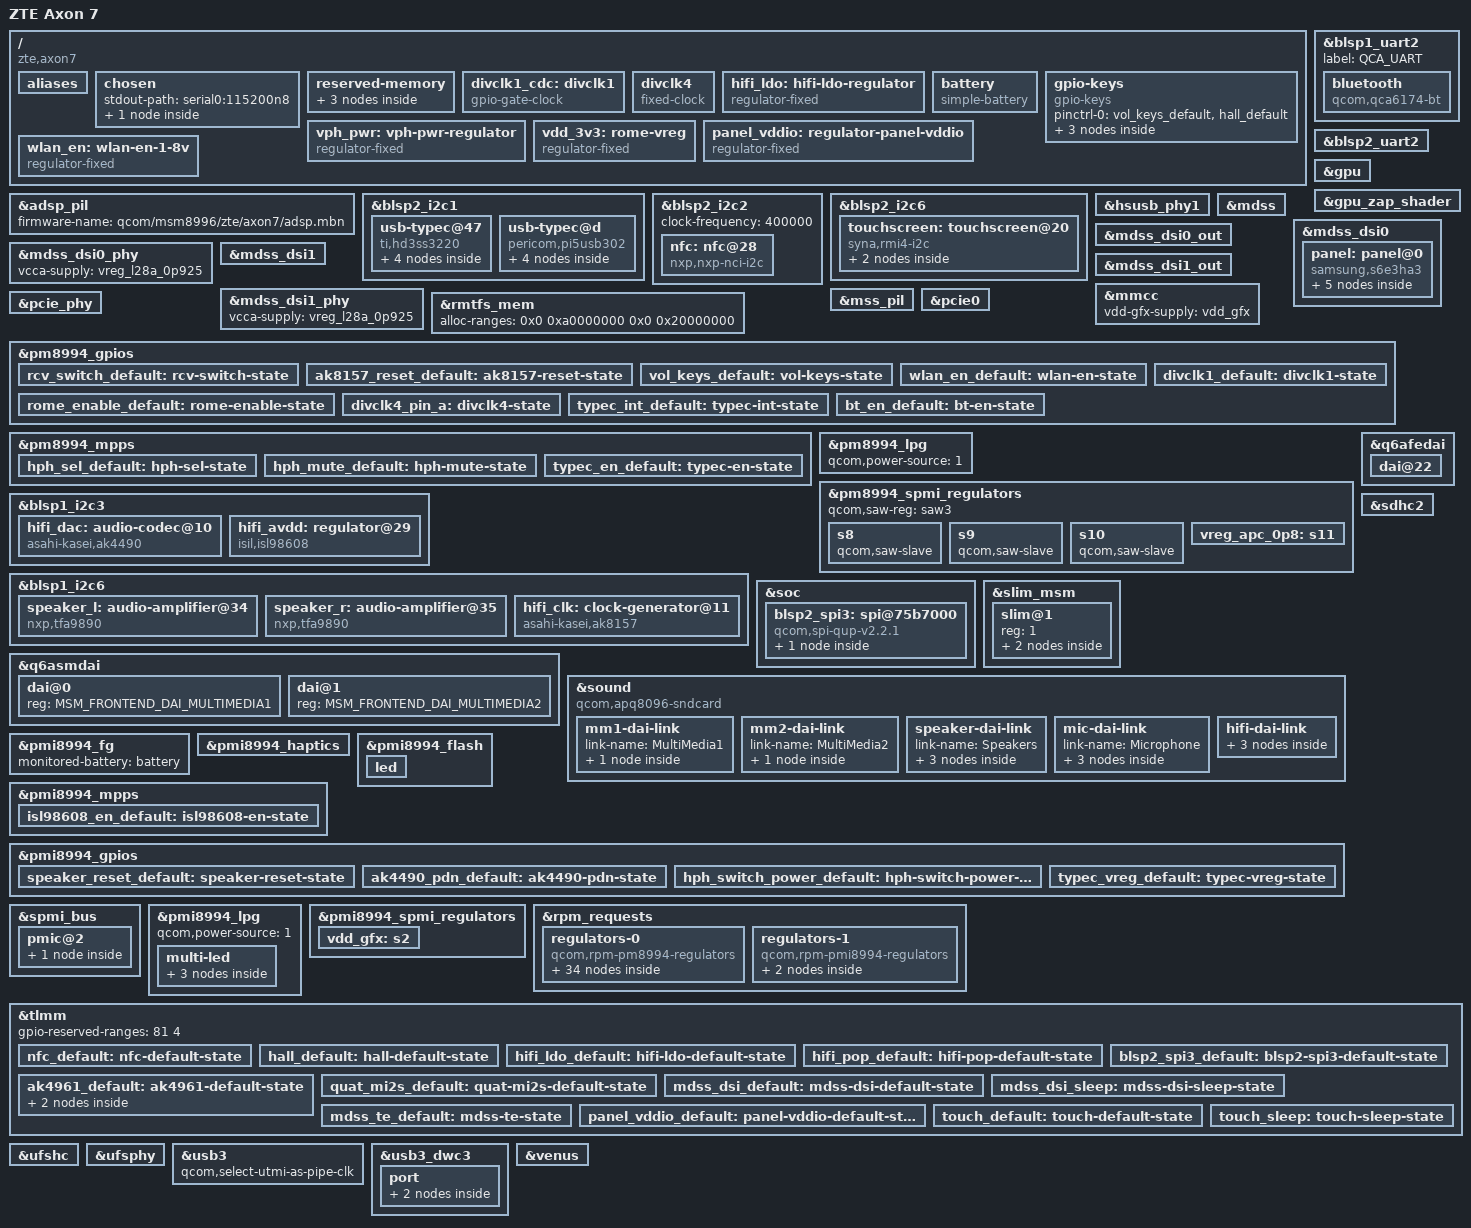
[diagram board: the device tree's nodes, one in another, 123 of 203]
// SPDX-License-Identifier: BSD-3-Clause
/*
 * ZTE Axon 7 (A2017/A2017G/A2017U, "ailsa_ii")
 *
 * Written against mainline msm8996.dtsi. Hardware description derived from
 * the device's downstream (3.18) device tree:
 *   model "Qualcomm Technologies, Inc. MSM 8996 v3 + PMI8996 MTP"
 * Board layout is very close to the Qualcomm MTP / Xiaomi msm8996 boards.
 */

/dts-v1/;

#include <dt-bindings/gpio/gpio.h>
#include <dt-bindings/input/input.h>
#include <dt-bindings/leds/common.h>
#include <dt-bindings/pinctrl/qcom,pmic-gpio.h>
#include <dt-bindings/sound/qcom,q6asm.h>
#include <dt-bindings/sound/qcom,q6dsp-lpass-ports.h>
#include "msm8996.dtsi"
#include "pm8994.dtsi"
#include "pmi8994.dtsi"
#include "pmi8996.dtsi"	/* sets qcom,pmic-id = <0x20009 0x10013 0 0>, as downstream */

/ {
	model = "ZTE Axon 7";
	compatible = "zte,axon7", "qcom,msm8996";
	chassis-type = "handset";

	/* Must match what the ZTE LK expects (taken from the downstream DT) */
	qcom,msm-id = <246 0x30001>;	/* MSM8996 v3.1 */
	qcom,board-id = <100 0>;

	aliases {
		serial0 = &blsp2_uart2;
		serial1 = &blsp1_uart2;
	};

	chosen {
		#address-cells = <2>;
		#size-cells = <2>;
		ranges;

		stdout-path = "serial0:115200n8";

		/*
		 * Bootloader continuous splash. Panel is a dual-DSI command-mode
		 * Samsung S6E3HA3 (1440x2560), bpp 24 in the downstream panel node.
		 * Format/stride are assumed (r8g8b8, 1440 * 3) as on other msm8996
		 * LK splash setups - to be confirmed on device.
		 */
		framebuffer0: framebuffer@83401000 {
			compatible = "simple-framebuffer";
			reg = <0x0 0x83401000 0x0 (1440 * 2560 * 3)>;
			width = <1440>;
			height = <2560>;
			stride = <(1440 * 3)>;
			format = "r8g8b8";

			/* MDP, both DSI links and MDP SMMU clocks */
			clocks = <&mmcc MDSS_MDP_CLK>,
				 <&mmcc MMSS_MMAGIC_AHB_CLK>,
				 <&mmcc MDSS_AHB_CLK>,
				 <&mmcc MDSS_AXI_CLK>,
				 <&mmcc MMSS_MISC_AHB_CLK>,
				 <&mmcc MDSS_BYTE0_CLK>,
				 <&mmcc MDSS_PCLK0_CLK>,
				 <&mmcc MDSS_ESC0_CLK>,
				 <&mmcc MDSS_BYTE1_CLK>,
				 <&mmcc MDSS_PCLK1_CLK>,
				 <&mmcc MDSS_ESC1_CLK>,
				 <&mmcc SMMU_MDP_AHB_CLK>,
				 <&mmcc SMMU_MDP_AXI_CLK>;

			power-domains = <&mmcc MDSS_GDSC>;
		};
	};

	reserved-memory {
		/* dfps_data_mem@83400000 (0x1000) + cont_splash_mem@83401000 (0x23ff000) */
		cont_splash_mem: memory@83400000 {
			reg = <0x0 0x83400000 0x0 0x2400000>;
			no-map;
		};

		/* Same location/layout as downstream pstore_mem, readable from TWRP */
		ramoops@bfc00000 {
			compatible = "ramoops";
			reg = <0x0 0xbfc00000 0x0 0x400000>;
			no-map;

			record-size = <0x8000>;
			console-size = <0x100000>;
			ftrace-size = <0x100000>;
			pmsg-size = <0x100000>;
		};

		/*
		 * ZTE "vlog": 1 MiB the bootloader hands to another writer
		 * (address and size in vendor IMEM); ZTE's kernel keeps it out
		 * of Linux, so do we.
		 */
		vlog@9ff00000 {
			reg = <0x0 0x9ff00000 0x0 0x100000>;
			no-map;
		};
	};

	divclk1_cdc: divclk1 {
		compatible = "gpio-gate-clock";
		clocks = <&rpmcc RPM_SMD_DIV_CLK1>;
		#clock-cells = <0>;
		enable-gpios = <&pm8994_gpios 15 GPIO_ACTIVE_HIGH>;

		pinctrl-names = "default";
		pinctrl-0 = <&divclk1_default>;
	};

	divclk4: divclk4 {
		compatible = "fixed-clock";
		#clock-cells = <0>;
		clock-frequency = <32768>;
		clock-output-names = "divclk4";

		pinctrl-names = "default";
		pinctrl-0 = <&divclk4_pin_a>;
	};

	hifi_ldo: hifi-ldo-regulator {
		compatible = "regulator-fixed";
		regulator-name = "hifi_ldo";
		gpio = <&tlmm 93 GPIO_ACTIVE_HIGH>;
		enable-active-high;
		pinctrl-names = "default";
		pinctrl-0 = <&hifi_ldo_default>;
	};

	/* ZTE P996A01, 3250 mAh, float voltage 4.4 V (zte_p996a01_3250mah.dtsi) */
	battery: battery {
		compatible = "simple-battery";
		charge-full-design-microamp-hours = <3250000>;
		voltage-min-design-microvolt = <3400000>;
		voltage-max-design-microvolt = <4400000>;
	};

	gpio-keys {
		compatible = "gpio-keys";

		pinctrl-names = "default";
		pinctrl-0 = <&vol_keys_default>, <&hall_default>;

		key-vol-up {
			label = "Volume Up";
			gpios = <&pm8994_gpios 2 GPIO_ACTIVE_LOW>;
			linux,code = <KEY_VOLUMEUP>;
			wakeup-source;
			debounce-interval = <15>;
		};

		key-vol-down {
			label = "Volume Down";
			gpios = <&pm8994_gpios 3 GPIO_ACTIVE_LOW>;
			linux,code = <KEY_VOLUMEDOWN>;
			wakeup-source;
			debounce-interval = <15>;
		};

		/*
		 * Hall sensor (downstream "zte-hall"/"ah,hall_ic", TLMM 124):
		 * high = cover open, low = cover closed (ZTE's ah1898.c). It is
		 * powered from PM8994 LVS2, which is kept on for it.
		 */
		event-hall-sensor {
			label = "Hall Effect Sensor";
			gpios = <&tlmm 124 GPIO_ACTIVE_LOW>;
			linux,input-type = <EV_SW>;
			linux,code = <SW_LID>;
			linux,can-disable;
			wakeup-source;
			debounce-interval = <150>;
		};
	};

	vph_pwr: vph-pwr-regulator {
		compatible = "regulator-fixed";
		regulator-name = "vph_pwr";
		regulator-min-microvolt = <3700000>;
		regulator-max-microvolt = <3700000>;
		regulator-always-on;
		regulator-boot-on;
	};

	/* downstream "rome_vreg", PM8994 GPIO 9 */
	vdd_3v3: rome-vreg {
		compatible = "regulator-fixed";
		regulator-name = "vdd_3v3";
		regulator-min-microvolt = <3300000>;
		regulator-max-microvolt = <3300000>;
		startup-delay-us = <4000>;
		vin-supply = <&vph_pwr_bbyp>;

		gpio = <&pm8994_gpios 9 GPIO_ACTIVE_HIGH>;
		enable-active-high;
		pinctrl-names = "default";
		pinctrl-0 = <&rome_enable_default>;

		/* Required by QCA6174a - vddpe-3v3 */
		regulator-always-on;
	};

	/* WL_EN pin (PM8994 GPIO 8) defined as a fixed regulator */
	/* panel VDD3 (1.8 V), downstream zte,lcd-3v-vsp-enable-gpio */
	panel_vddio: regulator-panel-vddio {
		compatible = "regulator-fixed";
		regulator-name = "panel_vddio";
		regulator-min-microvolt = <1800000>;
		regulator-max-microvolt = <1800000>;

		gpio = <&tlmm 40 GPIO_ACTIVE_HIGH>;
		enable-active-high;
		regulator-boot-on;

		pinctrl-names = "default";
		pinctrl-0 = <&panel_vddio_default>;
	};

	wlan_en: wlan-en-1-8v {
		compatible = "regulator-fixed";
		regulator-name = "wlan-en-regulator";
		regulator-min-microvolt = <1800000>;
		regulator-max-microvolt = <1800000>;

		gpio = <&pm8994_gpios 8 GPIO_ACTIVE_HIGH>;
		/* WLAN card specific delay */
		startup-delay-us = <70000>;
		enable-active-high;
		pinctrl-names = "default";
		pinctrl-0 = <&wlan_en_default>;
	};
};

&adsp_pil {
	status = "okay";
	firmware-name = "qcom/msm8996/zte/axon7/adsp.mbn";
};

&blsp1_uart2 {
	status = "okay";
	label = "QCA_UART";

	bluetooth: bluetooth {
		compatible = "qcom,qca6174-bt";

		/* bt_disable_n */
		enable-gpios = <&pm8994_gpios 19 GPIO_ACTIVE_HIGH>;
		clocks = <&divclk4>;

		pinctrl-names = "default";
		pinctrl-0 = <&bt_en_default>;
	};
};

/* Debug UART (downstream ttyHSL0) */
&blsp2_uart2 {
	status = "okay";
	label = "LS-UART1";
	pinctrl-names = "default", "sleep";
	pinctrl-0 = <&blsp2_uart2_2pins_default>;
	pinctrl-1 = <&blsp2_uart2_2pins_sleep>;
};

/*
 * i2c@7577000: isl98608@29 (hi-fi supply), ak4490@10 (AK4490 DAC)
 * i2c@757a000: ak8157@11
 * No mainline drivers yet, buses left disabled.
 */

/*
 * i2c@75b5000: TI HD3SS3220 USB-C controller @47 and SMB1351 parallel
 * charger @1d (no driver). Downstream zte-usb-type-c.dtsi: INT = PM8994
 * GPIO 14, EN_CC/mux = PM8994 MPP 5, SS re-driver = MPP 7, chip supplies
 * from PMI8994 GPIO 8 (VCONN 5 V) and GPIO 9 (3.3 V), all driven high.
 * Some units carry a Pericom PI5USB302 @0d instead: then this probe fails
 * and dwc3 stays in its default peripheral role (USB networking keeps
 * working). VBUS for host mode comes from the PMI8994 SMBCHG OTG boost.
 */
&blsp2_i2c1 {
	status = "okay";

	usb-typec@47 {
		compatible = "ti,hd3ss3220";
		reg = <0x47>;

		/* same trigger as the PI5USB302 node: both map PM8994 GPIO 14 */
		interrupts-extended = <&pm8994_gpios 14 IRQ_TYPE_LEVEL_LOW>;

		pinctrl-names = "default";
		pinctrl-0 = <&typec_int_default>, <&typec_en_default>, <&typec_vreg_default>;

		connector {
			compatible = "usb-c-connector";
			label = "USB-C";
			data-role = "dual";
			power-role = "dual";
			try-power-role = "sink";
			typec-power-opmode = "default";

			vbus-supply = <&smbchg_otg_vbus>;

			ports {
				#address-cells = <1>;
				#size-cells = <0>;

				port@0 {
					reg = <0>;

					typec_hs_out: endpoint {
						remote-endpoint = <&usb3_dwc3_role_in>;
					};
				};
			};
		};
	};

	/*
	 * Other units carry a Pericom PI5USB302 instead (downstream lists
	 * both, same INT and enables); this phone answers at 0x0d only.
	 */
	usb-typec@d {
		compatible = "pericom,pi5usb302";
		reg = <0x0d>;

		interrupts-extended = <&pm8994_gpios 14 IRQ_TYPE_LEVEL_LOW>;

		pinctrl-names = "default";
		pinctrl-0 = <&typec_int_default>, <&typec_en_default>, <&typec_vreg_default>;

		connector {
			compatible = "usb-c-connector";
			label = "USB-C";
			data-role = "dual";
			power-role = "dual";
			try-power-role = "sink";
			typec-power-opmode = "default";

			vbus-supply = <&smbchg_otg_vbus>;

			ports {
				#address-cells = <1>;
				#size-cells = <0>;

				port@0 {
					reg = <0>;

					pi5usb_hs_out: endpoint {
						remote-endpoint = <&usb3_dwc3_role_pi>;
					};
				};
			};
		};
	};
};

&blsp2_i2c2 {
	status = "okay";
	clock-frequency = <400000>;

	/* downstream "qcom,nq-nci" (NXP PN5xx) */
	nfc: nfc@28 {
		compatible = "nxp,nxp-nci-i2c";
		reg = <0x28>;

		interrupt-parent = <&tlmm>;
		interrupts = <9 IRQ_TYPE_LEVEL_HIGH>;

		enable-gpios = <&tlmm 12 GPIO_ACTIVE_HIGH>;
		firmware-gpios = <&tlmm 96 GPIO_ACTIVE_HIGH>;

		pinctrl-names = "default";
		pinctrl-0 = <&nfc_default>;
	};
};

&blsp2_i2c6 {
	status = "okay";

	/* Synaptics DSX (S3320-class) */
	touchscreen: touchscreen@20 {
		compatible = "syna,rmi4-i2c";
		reg = <0x20>;
		#address-cells = <1>;
		#size-cells = <0>;

		interrupts-extended = <&tlmm 125 IRQ_TYPE_LEVEL_LOW>;
		reset-gpios = <&tlmm 89 GPIO_ACTIVE_LOW>;

		/* downstream: vdd_ana = L14 (1.8 V), vcc_i2c = L22 (3.3 V) */
		vdd-supply = <&vreg_l22a_3p3>;
		vio-supply = <&vreg_l14a_1p8>;

		pinctrl-names = "default", "sleep";
		pinctrl-0 = <&touch_default>;
		pinctrl-1 = <&touch_sleep>;

		syna,reset-delay-ms = <100>;
		syna,startup-delay-ms = <100>;

		rmi4-f01@1 {
			reg = <0x1>;
			syna,nosleep-mode = <1>;
		};

		rmi4-f12@12 {
			reg = <0x12>;
			syna,sensor-type = <1>;
			touchscreen-x-mm = <68>;
			touchscreen-y-mm = <121>;
		};
	};

	/* ndt,stress-i2c pressure sensor @50: no mainline driver */
};

&gpu {
	status = "okay";
};

&gpu_zap_shader {
	firmware-name = "qcom/msm8996/zte/axon7/a530_zap.mbn";
};

&hsusb_phy1 {
	status = "okay";

	vdd-supply = <&vreg_l28a_0p925>;
	vdda-pll-supply = <&vreg_l12a_1p8>;
	vdda-phy-dpdm-supply = <&vreg_l24a_3p075>;
};

/*
 * Display: Samsung S6E3HA3 1440x2560 AMOLED, command mode, over both DSI
 * links (bonded DSI, DSI0 master, each link one 720x2560 half). Bonded DSI
 * needs the DPU driver (msm.prefer_mdp5=0); MDP5 drives single DSI only.
 * simplefb above keeps LK's splash until the DRM driver takes over.
 */
&mdss {
	status = "okay";
};

&mdss_dsi0 {
	status = "okay";

	vdda-supply = <&vreg_l2a_1p25>;
	vcca-supply = <&vreg_l28a_0p925>;
	vddio-supply = <&vreg_l14a_1p8>;

	qcom,dual-dsi-mode;
	qcom,master-dsi;
	qcom,sync-dual-dsi;

	pinctrl-names = "default", "sleep";
	pinctrl-0 = <&mdss_dsi_default &mdss_te_default>;
	pinctrl-1 = <&mdss_dsi_sleep &mdss_te_default>;

	panel: panel@0 {
		compatible = "samsung,s6e3ha3";
		reg = <0>;

		vddio-supply = <&panel_vddio>;
		vdda-supply = <&vreg_l19a_3p0>;
		reset-gpios = <&tlmm 8 GPIO_ACTIVE_LOW>;

		ports {
			#address-cells = <1>;
			#size-cells = <0>;

			port@0 {
				reg = <0>;

				panel_in0: endpoint {
					remote-endpoint = <&mdss_dsi0_out>;
				};
			};

			port@1 {
				reg = <1>;

				panel_in1: endpoint {
					remote-endpoint = <&mdss_dsi1_out>;
				};
			};
		};
	};
};

&mdss_dsi0_out {
	remote-endpoint = <&panel_in0>;
	data-lanes = <0 1 2 3>;
};

&mdss_dsi0_phy {
	status = "okay";

	vcca-supply = <&vreg_l28a_0p925>;
};

&mdss_dsi1 {
	status = "okay";

	vdda-supply = <&vreg_l2a_1p25>;
	vcca-supply = <&vreg_l28a_0p925>;
	vddio-supply = <&vreg_l14a_1p8>;

	qcom,dual-dsi-mode;
	qcom,sync-dual-dsi;

	/* bonded: DSI1 runs from DSI0's PLL */
	assigned-clock-parents = <&mdss_dsi0_phy DSI_BYTE_PLL_CLK>,
				 <&mdss_dsi0_phy DSI_PIXEL_PLL_CLK>;
};

&mdss_dsi1_out {
	remote-endpoint = <&panel_in1>;
	data-lanes = <0 1 2 3>;
};

&mdss_dsi1_phy {
	status = "okay";

	vcca-supply = <&vreg_l28a_0p925>;
};

&mmcc {
	vdd-gfx-supply = <&vdd_gfx>;
};

/*
 * The bootloader loads the kernel and initramfs at 0xa0000000, inside the
 * 32 MiB the SoC dtsi allows for rmtfs: no room is left and the modem cannot
 * start. Allow the whole 512 MiB above it.
 */
&rmtfs_mem {
	alloc-ranges = <0x0 0xa0000000 0x0 0x20000000>;
};

&mss_pil {
	status = "okay";

	pll-supply = <&vreg_l12a_1p8>;

	firmware-name = "qcom/msm8996/zte/axon7/mba.mbn",
			"qcom/msm8996/zte/axon7/modem.mbn";
};

&pcie0 {
	status = "okay";

	/* Supplied by vdd_3v3, but choose wlan_en to drive enable pin high */
	vddpe-3v3-supply = <&wlan_en>;
	vdda-supply = <&vreg_l28a_0p925>;

	perst-gpios = <&tlmm 35 GPIO_ACTIVE_LOW>;
	wake-gpios = <&tlmm 37 GPIO_ACTIVE_HIGH>;
};

&pcie_phy {
	status = "okay";

	vdda-phy-supply = <&vreg_l28a_0p925>;
	vdda-pll-supply = <&vreg_l12a_1p8>;
};

&pm8994_gpios {
	/* earpiece switch (ZTE qcom,rcv-sw-gpio) */
	rcv_switch_default: rcv-switch-state {
		pins = "gpio13";
		function = PMIC_GPIO_FUNC_NORMAL;
		output-low;
		bias-disable;
		power-source = <PM8994_GPIO_S4>;
	};

	/* Hi-Fi: AK8157 clock generator reset (GPIO 1, and GPIO 12 as in ZTE's tree) */
	ak8157_reset_default: ak8157-reset-state {
		pins = "gpio1", "gpio12";
		function = PMIC_GPIO_FUNC_NORMAL;
		output-low;
		bias-disable;
		power-source = <PM8994_GPIO_S4>;
	};

	vol_keys_default: vol-keys-state {
		pins = "gpio2", "gpio3";
		function = PMIC_GPIO_FUNC_NORMAL;
		input-enable;
		bias-pull-up;
		qcom,drive-strength = <PMIC_GPIO_STRENGTH_NO>;
		power-source = <PM8994_GPIO_S4>;
	};

	wlan_en_default: wlan-en-state {
		pins = "gpio8";
		function = PMIC_GPIO_FUNC_NORMAL;
		output-low;
		qcom,drive-strength = <PMIC_GPIO_STRENGTH_LOW>;
		power-source = <PM8994_GPIO_S4>;
		bias-disable;
	};

	rome_enable_default: rome-enable-state {
		pins = "gpio9";
		function = PMIC_GPIO_FUNC_NORMAL;
		output-high;
		qcom,drive-strength = <PMIC_GPIO_STRENGTH_LOW>;
		power-source = <PM8994_GPIO_VPH>;
	};

	divclk1_default: divclk1-state {
		pins = "gpio15";
		function = PMIC_GPIO_FUNC_FUNC1;
		bias-disable;
		power-source = <PM8994_GPIO_S4>;
		qcom,drive-strength = <PMIC_GPIO_STRENGTH_LOW>;
	};

	divclk4_pin_a: divclk4-state {
		pins = "gpio18";
		function = PMIC_GPIO_FUNC_FUNC2;
		bias-disable;
		power-source = <PM8994_GPIO_S4>;
	};

	typec_int_default: typec-int-state {
		pins = "gpio14";
		function = PMIC_GPIO_FUNC_NORMAL;
		input-enable;
		bias-disable;
		power-source = <PM8994_GPIO_S4>;
	};

	bt_en_default: bt-en-state {
		pins = "gpio19";
		function = PMIC_GPIO_FUNC_NORMAL;
		output-low;
		power-source = <PM8994_GPIO_S4>;
		qcom,drive-strength = <PMIC_GPIO_STRENGTH_LOW>;
		bias-pull-down;
	};
};

&pm8994_mpps {
	/* Hi-Fi: ISL54405 headphone switch select, MPP 2 (0 = AK4490, 1 = AK4961) */
	hph_sel_default: hph-sel-state {
		pins = "mpp2";
		function = "digital";
		output-low;
		power-source = <2>;
	};

	/* Hi-Fi: ISL54405 mute, MPP 4 (1 = muted) */
	hph_mute_default: hph-mute-state {
		pins = "mpp4";
		function = "digital";
		output-high;
		power-source = <2>;
	};

	typec_en_default: typec-en-state {
		/* MPP 5: EN_CC / USB 3.0 mux, MPP 7: SS re-driver; enabled high */
		pins = "mpp5", "mpp7";
		function = "digital";
		output-high;
		power-source = <2>;
	};
};

&pm8994_lpg {
	status = "okay";

	qcom,power-source = <1>;
};

&pm8994_spmi_regulators {
	qcom,saw-reg = <&saw3>;

	s8 {
		qcom,saw-slave;
	};

	s9 {
		qcom,saw-slave;
	};

	s10 {
		qcom,saw-slave;
	};

	vreg_apc_0p8: s11 {
		qcom,saw-leader;
		regulator-name = "vreg_apc_0p8";
		regulator-min-microvolt = <470000>;
		regulator-max-microvolt = <1140000>;
		regulator-max-step-microvolt = <150000>;
		regulator-always-on;
	};
};

/* Notification LED, downstream qpnp RGB (ids 3/4/5 = R/G/B) */
/*
 * Hi-Fi headphone path (ZTE's msm-3.18 tree): AK4490 DAC and ISL98608
 * supply on BLSP1 QUP3, AK8157 clock generator (the I2S clock provider)
 * on BLSP1 QUP6, Quaternary MI2S from the ADSP, and an ISL54405 switch
 * that connects the jack to the AK4490 (or to the AK4961, which has no
 * driver yet, so the switch stays on the AK4490).
 */
&blsp1_i2c3 {
	status = "okay";

	hifi_dac: audio-codec@10 {
		compatible = "asahi-kasei,ak4490";
		reg = <0x10>;
		#sound-dai-cells = <0>;

		dvdd-supply = <&hifi_ldo>;
		avdd-supply = <&hifi_avdd>;
		pdn-gpios = <&pmi8994_gpios 1 GPIO_ACTIVE_LOW>;
		/* ISL54405 mute, high = muted */
		mute-gpios = <&pm8994_mpps 4 GPIO_ACTIVE_HIGH>;

		pinctrl-names = "default";
		pinctrl-0 = <&ak4490_pdn_default &hph_mute_default &hph_sel_default
			     &hph_switch_power_default &hifi_pop_default>;
	};

	hifi_avdd: regulator@29 {
		compatible = "isil,isl98608";
		reg = <0x29>;
		regulator-name = "hifi_avdd";
		enable-gpios = <&pmi8994_mpps 4 GPIO_ACTIVE_HIGH>;

		pinctrl-names = "default";
		pinctrl-0 = <&isl98608_en_default>;
	};
};

&blsp1_i2c6 {
	status = "okay";

	/*
	 * TFA9890 speaker amplifiers, fed by the AK4961's PORT2 (SDTO2) I2S;
	 * resets on PMI8994 GPIO 2/3 (low = running). 0x34 drives the bottom
	 * speaker (next to the microphone), 0x35 the top one, which the
	 * receiver switch turns into the earpiece (measured with the
	 * microphone, 2026-11-09).
	 */
	speaker_l: audio-amplifier@34 {
		compatible = "nxp,tfa9890";
		reg = <0x34>;
		#sound-dai-cells = <0>;
		sound-name-prefix = "Speaker Bottom";
		vddd-supply = <&vreg_s4a_1p8>;

		pinctrl-names = "default";
		pinctrl-0 = <&speaker_reset_default>;
	};

	speaker_r: audio-amplifier@35 {
		compatible = "nxp,tfa9890";
		reg = <0x35>;
		#sound-dai-cells = <0>;
		sound-name-prefix = "Speaker Top";
		vddd-supply = <&vreg_s4a_1p8>;
		/* ZTE's "Receiver Switch" (PM8994 GPIO 13): top speaker as earpiece */
		rcv-gpios = <&pm8994_gpios 13 GPIO_ACTIVE_HIGH>;

		pinctrl-names = "default";
		pinctrl-0 = <&rcv_switch_default>;
	};

	hifi_clk: clock-generator@11 {
		compatible = "asahi-kasei,ak8157";
		reg = <0x11>;
		#sound-dai-cells = <0>;
		reset-gpios = <&pm8994_gpios 1 GPIO_ACTIVE_LOW>,
			      <&pm8994_gpios 12 GPIO_ACTIVE_LOW>;

		pinctrl-names = "default";
		pinctrl-0 = <&ak8157_reset_default>;
	};
};

/*
 * AK4961 main codec (speaker, earpiece, microphones, headset). ZTE runs it
 * in "SLIMbus + SPI" mode: registers over SPI on BLSP2 QUP3 (CIF1 low),
 * audio data and the port arrays over SLIMbus.
 */
&soc {
	blsp2_spi3: spi@75b7000 {
		compatible = "qcom,spi-qup-v2.2.1";
		reg = <0x075b7000 0x600>;
		interrupts = <GIC_SPI 103 IRQ_TYPE_LEVEL_HIGH>;
		clocks = <&gcc GCC_BLSP2_QUP3_SPI_APPS_CLK>,
			 <&gcc GCC_BLSP2_AHB_CLK>;
		clock-names = "core", "iface";
		dmas = <&blsp2_dma 16>, <&blsp2_dma 17>;
		dma-names = "tx", "rx";
		pinctrl-names = "default";
		pinctrl-0 = <&blsp2_spi3_default>;
		#address-cells = <1>;
		#size-cells = <0>;

		ak4961_spi: codec@0 {
			compatible = "asahi-kasei,ak4961-spi";
			reg = <0>;
			spi-max-frequency = <9600000>;
		};
	};
};

&slim_msm {
	status = "okay";

	slim@1 {
		reg = <1>;
		#address-cells = <2>;
		#size-cells = <0>;

		ak4961_ifd: ifd@0,0 {
			compatible = "slim1dd,4961";
			reg = <0 0>;
		};

		ak4961: codec@2,0 {
			compatible = "slim1dd,4961";
			reg = <2 0>;
			#sound-dai-cells = <1>;

			slim-ifc-dev = <&ak4961_ifd>;
			akm,spi = <&ak4961_spi>;

			clocks = <&divclk1_cdc>;
			clock-names = "mclk";

			ldo-gpios = <&tlmm 63 GPIO_ACTIVE_HIGH>;
			cif-gpios = <&tlmm 62 GPIO_ACTIVE_HIGH>;
			reset-gpios = <&tlmm 64 GPIO_ACTIVE_LOW>;

			pinctrl-names = "default";
			pinctrl-0 = <&ak4961_default>;
		};
	};
};

&q6afedai {
	dai@22 {
		reg = <QUATERNARY_MI2S_RX>;
		/* ZTE: qcom,msm-mi2s-rx-lines = <2> (bit 1, SD1 on TLMM 61) */
		qcom,sd-lines = <1>;
	};
};

&q6asmdai {
	dai@0 {
		reg = <MSM_FRONTEND_DAI_MULTIMEDIA1>;
	};

	dai@1 {
		reg = <MSM_FRONTEND_DAI_MULTIMEDIA2>;
	};
};

&sound {
	compatible = "qcom,apq8096-sndcard";
	model = "ZTE Axon 7";

	pinctrl-names = "default";
	pinctrl-0 = <&quat_mi2s_default>;

	mm1-dai-link {
		link-name = "MultiMedia1";

		cpu {
			sound-dai = <&q6asmdai MSM_FRONTEND_DAI_MULTIMEDIA1>;
		};
	};

	mm2-dai-link {
		link-name = "MultiMedia2";

		cpu {
			sound-dai = <&q6asmdai MSM_FRONTEND_DAI_MULTIMEDIA2>;
		};
	};

	speaker-dai-link {
		link-name = "Speakers";

		cpu {
			sound-dai = <&q6afedai SLIMBUS_0_RX>;
		};

		platform {
			sound-dai = <&q6routing>;
		};

		codec {
			sound-dai = <&ak4961 0>, <&speaker_l>, <&speaker_r>;
		};
	};

	mic-dai-link {
		link-name = "Microphone";

		cpu {
			sound-dai = <&q6afedai SLIMBUS_0_TX>;
		};

		platform {
			sound-dai = <&q6routing>;
		};

		codec {
			sound-dai = <&ak4961 1>;
		};
	};

	hifi-dai-link {
		link-name = "Hi-Fi Headphones";
		/* BCLK and WS come from the AK8157 */
		qcom,mi2s-clock-consumer;

		cpu {
			sound-dai = <&q6afedai QUATERNARY_MI2S_RX>;
		};

		platform {
			sound-dai = <&q6routing>;
		};

		codec {
			sound-dai = <&hifi_dac>, <&hifi_clk>;
		};
	};
};

&pmi8994_fg {
	/* read-only: no charger driver yet, so no "power-supplies" */
	monitored-battery = <&battery>;
	status = "okay";
};

/* LRA vibrator, ZTE's msm-pmi8994.dtsi values (buffer mode, sine) */
&pmi8994_haptics {
	qcom,wave-play-rate-us = <4255>;
	qcom,brake-pattern = [03 03 00 00];
	qcom,vmax-microvolt = <2668000>;
	status = "okay";
};

/* rear dual-tone flash, torch mode */
&pmi8994_flash {
	status = "okay";

	led {
		function = LED_FUNCTION_TORCH;
		color = <LED_COLOR_ID_WHITE>;
	};
};

&pmi8994_mpps {
	/* Hi-Fi: ISL98608 supply enable (MPP 4) */
	isl98608_en_default: isl98608-en-state {
		pins = "mpp4";
		function = "digital";
		output-low;
		power-source = <2>;
	};
};

&pmi8994_gpios {
	/* TFA9890 speaker amplifier resets (GPIO 2 and 3, ZTE SPKR_SD_N), low = running */
	speaker_reset_default: speaker-reset-state {
		pins = "gpio2", "gpio3";
		function = PMIC_GPIO_FUNC_NORMAL;
		output-low;
		bias-disable;
		power-source = <PM8994_GPIO_S4>;
	};

	/* Hi-Fi: AK4490 PDN (GPIO 1), ISL54405 switch power (GPIO 10) */
	ak4490_pdn_default: ak4490-pdn-state {
		pins = "gpio1";
		function = PMIC_GPIO_FUNC_NORMAL;
		output-low;
		bias-disable;
		power-source = <PM8994_GPIO_S4>;
	};

	hph_switch_power_default: hph-switch-power-state {
		pins = "gpio10";
		function = PMIC_GPIO_FUNC_NORMAL;
		output-high;
		bias-disable;
		power-source = <PM8994_GPIO_S4>;
	};

	typec_vreg_default: typec-vreg-state {
		/* GPIO 8: VCONN 5 V regulator enable, GPIO 9: HD3SS3220 3.3 V */
		pins = "gpio8", "gpio9";
		function = PMIC_GPIO_FUNC_NORMAL;
		output-high;
		power-source = <PM8994_GPIO_VPH>;
		qcom,drive-strength = <PMIC_GPIO_STRENGTH_LOW>;
	};
};

&spmi_bus {
	pmic@2 {
		/* SMBCHG OTG (0x1100) and BAT_IF (0x1200) peripherals */
		smbchg_otg_vbus: usb-vbus-regulator@1100 {
			compatible = "qcom,pmi8994-smbchg-otg";
			reg = <0x1100>, <0x1200>;
			regulator-name = "smbchg_otg_vbus";
			regulator-min-microvolt = <5000000>;
			regulator-max-microvolt = <5000000>;
		};
	};
};

&pmi8994_lpg {
	status = "okay";

	qcom,power-source = <1>;

	multi-led {
		color = <LED_COLOR_ID_RGB>;
		function = LED_FUNCTION_STATUS;

		#address-cells = <1>;
		#size-cells = <0>;

		led@1 {
			reg = <1>;
			color = <LED_COLOR_ID_BLUE>;
		};

		led@2 {
			reg = <2>;
			color = <LED_COLOR_ID_GREEN>;
		};

		led@3 {
			reg = <3>;
			color = <LED_COLOR_ID_RED>;
		};
	};
};

&pmi8994_spmi_regulators {
	vdd_gfx: s2 {
		regulator-name = "vdd_gfx";
		regulator-min-microvolt = <400000>;
		regulator-max-microvolt = <1015000>;
		regulator-enable-ramp-delay = <500>;
	};
};

&rpm_requests {
	regulators-0 {
		compatible = "qcom,rpm-pm8994-regulators";

		vdd_s1-supply = <&vph_pwr>;
		vdd_s2-supply = <&vph_pwr>;
		vdd_s3-supply = <&vph_pwr>;
		vdd_s4-supply = <&vph_pwr>;
		vdd_s5-supply = <&vph_pwr>;
		vdd_s6-supply = <&vph_pwr>;
		vdd_s7-supply = <&vph_pwr>;
		vdd_s8-supply = <&vph_pwr>;
		vdd_s9-supply = <&vph_pwr>;
		vdd_s10-supply = <&vph_pwr>;
		vdd_s11-supply = <&vph_pwr>;
		vdd_s12-supply = <&vph_pwr>;
		vdd_l1-supply = <&vreg_s1b_1p025>;
		vdd_l2_l26_l28-supply = <&vreg_s3a_1p3>;
		vdd_l3_l11-supply = <&vreg_s3a_1p3>;
		vdd_l4_l27_l31-supply = <&vreg_s3a_1p3>;
		vdd_l5_l7-supply = <&vreg_s5a_2p15>;
		vdd_l6_l12_l32-supply = <&vreg_s5a_2p15>;
		vdd_l8_l16_l30-supply = <&vph_pwr>;
		vdd_l9_l10_l18_l22-supply = <&vph_pwr_bbyp>;
		vdd_l13_l19_l23_l24-supply = <&vph_pwr_bbyp>;
		vdd_l14_l15-supply = <&vreg_s5a_2p15>;
		vdd_l17_l29-supply = <&vph_pwr_bbyp>;
		vdd_l20_l21-supply = <&vph_pwr_bbyp>;
		vdd_l25-supply = <&vreg_s3a_1p3>;
		vdd_lvs1_2-supply = <&vreg_s4a_1p8>;

		/* Voltages below are from the downstream rpm-regulator nodes */
		vreg_s3a_1p3: s3 {
			regulator-name = "vreg_s3a_1p3";
			regulator-min-microvolt = <1300000>;
			regulator-max-microvolt = <1300000>;

			/* Required by QCA6174a - vdd-core */
			regulator-always-on;
		};

		vreg_s4a_1p8: s4 {
			regulator-name = "vreg_s4a_1p8";
			regulator-min-microvolt = <1800000>;
			regulator-max-microvolt = <1800000>;
			regulator-allow-set-load;

			/* Required by QCA6174a - vddio, also UFS vccq2 */
			regulator-always-on;
		};

		vreg_s5a_2p15: s5 {
			regulator-name = "vreg_s5a_2p15";
			regulator-min-microvolt = <2150000>;
			regulator-max-microvolt = <2150000>;
		};

		vreg_s7a_0p8: s7 {
			regulator-name = "vreg_s7a_0p8";
			regulator-min-microvolt = <800000>;
			regulator-max-microvolt = <800000>;
		};

		vreg_l1a_1p0: l1 {
			regulator-name = "vreg_l1a_1p0";
			regulator-min-microvolt = <1000000>;
			regulator-max-microvolt = <1000000>;
		};

		vreg_l2a_1p25: l2 {
			regulator-name = "vreg_l2a_1p25";
			regulator-min-microvolt = <1250000>;
			regulator-max-microvolt = <1250000>;
		};

		vreg_l3a_0p85: l3 {
			regulator-name = "vreg_l3a_0p85";
			regulator-min-microvolt = <850000>;
			regulator-max-microvolt = <850000>;
		};

		vreg_l4a_1p225: l4 {
			regulator-name = "vreg_l4a_1p225";
			regulator-min-microvolt = <1225000>;
			regulator-max-microvolt = <1225000>;
		};

		vreg_l6a_1p2: l6 {
			regulator-name = "vreg_l6a_1p2";
			regulator-min-microvolt = <1200000>;
			regulator-max-microvolt = <1200000>;
		};

		vreg_l8a_1p8: l8 {
			regulator-name = "vreg_l8a_1p8";
			regulator-min-microvolt = <1800000>;
			regulator-max-microvolt = <1800000>;
		};

		vreg_l9a_1p8: l9 {
			regulator-name = "vreg_l9a_1p8";
			regulator-min-microvolt = <1800000>;
			regulator-max-microvolt = <1800000>;
		};

		vreg_l10a_1p8: l10 {
			regulator-name = "vreg_l10a_1p8";
			regulator-min-microvolt = <1800000>;
			regulator-max-microvolt = <1800000>;
		};

		vreg_l11a_1p15: l11 {
			regulator-name = "vreg_l11a_1p15";
			regulator-min-microvolt = <1150000>;
			regulator-max-microvolt = <1150000>;
		};

		vreg_l12a_1p8: l12 {
			regulator-name = "vreg_l12a_1p8";
			regulator-min-microvolt = <1800000>;
			regulator-max-microvolt = <1800000>;
			regulator-allow-set-load;
		};

		vreg_l13a_2p95: l13 {
			regulator-name = "vreg_l13a_2p95";
			regulator-min-microvolt = <1800000>;
			regulator-max-microvolt = <2950000>;
		};

		vreg_l14a_1p8: l14 {
			regulator-name = "vreg_l14a_1p8";
			regulator-min-microvolt = <1800000>;
			regulator-max-microvolt = <1800000>;
		};

		vreg_l15a_1p8: l15 {
			regulator-name = "vreg_l15a_1p8";
			regulator-min-microvolt = <1800000>;
			regulator-max-microvolt = <1800000>;
		};

		vreg_l16a_2p7: l16 {
			regulator-name = "vreg_l16a_2p7";
			regulator-min-microvolt = <2700000>;
			regulator-max-microvolt = <2700000>;
		};

		vreg_l17a_2p9: l17 {
			regulator-name = "vreg_l17a_2p9";
			regulator-min-microvolt = <2900000>;
			regulator-max-microvolt = <2900000>;
		};

		vreg_l18a_2p7: l18 {
			regulator-name = "vreg_l18a_2p7";
			regulator-min-microvolt = <2700000>;
			regulator-max-microvolt = <2900000>;
		};

		vreg_l19a_3p0: l19 {
			regulator-name = "vreg_l19a_3p0";
			regulator-min-microvolt = <3000000>;
			regulator-max-microvolt = <3000000>;
		};

		vreg_l20a_2p95: l20 {
			regulator-name = "vreg_l20a_2p95";
			regulator-min-microvolt = <2950000>;
			regulator-max-microvolt = <2950000>;
			regulator-allow-set-load;
		};

		vreg_l21a_2p95: l21 {
			regulator-name = "vreg_l21a_2p95";
			regulator-min-microvolt = <2950000>;
			regulator-max-microvolt = <2950000>;
			regulator-allow-set-load;
		};

		vreg_l22a_3p3: l22 {
			regulator-name = "vreg_l22a_3p3";
			regulator-min-microvolt = <3300000>;
			regulator-max-microvolt = <3300000>;
		};

		vreg_l23a_2p8: l23 {
			regulator-name = "vreg_l23a_2p8";
			regulator-min-microvolt = <2800000>;
			regulator-max-microvolt = <2800000>;
		};

		vreg_l24a_3p075: l24 {
			regulator-name = "vreg_l24a_3p075";
			regulator-min-microvolt = <3075000>;
			regulator-max-microvolt = <3075000>;
		};

		vreg_l25a_1p2: l25 {
			regulator-name = "vreg_l25a_1p2";
			regulator-min-microvolt = <1200000>;
			regulator-max-microvolt = <1200000>;
			regulator-allow-set-load;
		};

		vreg_l27a_1p0: l27 {
			regulator-name = "vreg_l27a_1p0";
			regulator-min-microvolt = <1000000>;
			regulator-max-microvolt = <1000000>;
		};

		vreg_l28a_0p925: l28 {
			regulator-name = "vreg_l28a_0p925";
			regulator-min-microvolt = <925000>;
			regulator-max-microvolt = <925000>;
			regulator-allow-set-load;
		};

		vreg_l29a_2p8: l29 {
			regulator-name = "vreg_l29a_2p8";
			regulator-min-microvolt = <2800000>;
			regulator-max-microvolt = <2800000>;
		};

		vreg_l30a_1p8: l30 {
			regulator-name = "vreg_l30a_1p8";
			regulator-min-microvolt = <1800000>;
			regulator-max-microvolt = <1800000>;

			/* Required by QCA6174a - vddio-xtal */
			regulator-always-on;
		};

		vreg_l32a_1p8: l32 {
			regulator-name = "vreg_l32a_1p8";
			regulator-min-microvolt = <1800000>;
			regulator-max-microvolt = <1800000>;
		};

		vreg_lvs1a_1p8: lvs1 {
			regulator-name = "vreg_lvs1a_1p8";
		};

		/* hall sensor supply (downstream zte-hall vddio-supply) */
		vreg_lvs2a_1p8: lvs2 {
			regulator-name = "vreg_lvs2a_1p8";
			regulator-always-on;
		};
	};

	regulators-1 {
		compatible = "qcom,rpm-pmi8994-regulators";

		vdd_s1-supply = <&vph_pwr>;
		vdd_s2-supply = <&vph_pwr>;
		vdd_s3-supply = <&vph_pwr>;
		vdd_bst_byp-supply = <&vph_pwr>;

		vreg_s1b_1p025: s1 {
			regulator-name = "vreg_s1b_1p025";
			regulator-min-microvolt = <1025000>;
			regulator-max-microvolt = <1025000>;
		};

		vph_pwr_bbyp: boost-bypass {
			regulator-name = "vph_pwr_bbyp";
			regulator-min-microvolt = <3150000>;
			regulator-max-microvolt = <3600000>;
		};
	};
};

/* External microSD */
&sdhc2 {
	status = "okay";

	/* card detect polarity unverified (downstream: tlmm 95): poll instead */
	broken-cd;
	vmmc-supply = <&vreg_l21a_2p95>;
	vqmmc-supply = <&vreg_l13a_2p95>;
};

&tlmm {
	/* blsp_spi5 (fingerprint) is owned by TZ */
	gpio-reserved-ranges = <81 4>;

	nfc_default: nfc-default-state {
		pins = "gpio12", "gpio96";
		function = "gpio";
		drive-strength = <16>;
		bias-pull-up;
	};

	hall_default: hall-default-state {
		pins = "gpio124";
		function = "gpio";
		drive-strength = <2>;
		bias-disable;
	};

	/* Hi-Fi: AK4490 LDO enable */
	hifi_ldo_default: hifi-ldo-default-state {
		pins = "gpio93";
		function = "gpio";
		drive-strength = <2>;
		bias-disable;
	};

	/* Hi-Fi: output anti-pop switch, high while the Hi-Fi path is used (ZTE) */
	hifi_pop_default: hifi-pop-default-state {
		pins = "gpio74";
		function = "gpio";
		drive-strength = <2>;
		bias-disable;
		output-high;
	};

	/* AK4961 control port (BLSP2 QUP3 SPI, ZTE spi_9) */
	blsp2_spi3_default: blsp2-spi3-default-state {
		pins = "gpio49", "gpio50", "gpio51", "gpio52";
		function = "blsp_spi9";
		drive-strength = <6>;
		bias-disable;
	};

	/* AK4961: CIF1 62, LDO 63, reset 64, interrupt 54 */
	ak4961_default: ak4961-default-state {
		ctrl-pins {
			pins = "gpio62", "gpio63", "gpio64";
			function = "gpio";
			drive-strength = <16>;
			bias-disable;
		};

		irq-pins {
			pins = "gpio54";
			function = "gpio";
			drive-strength = <2>;
			bias-pull-up;
		};
	};

	/* Quaternary MI2S: SCK 58, WS 59 (both from the AK8157), SD1 61 */
	quat_mi2s_default: quat-mi2s-default-state {
		pins = "gpio58", "gpio59", "gpio61";
		function = "qua_mi2s";
		drive-strength = <8>;
		bias-disable;
	};

	mdss_dsi_default: mdss-dsi-default-state {
		pins = "gpio8";
		function = "gpio";
		drive-strength = <8>;
		bias-disable;
	};

	mdss_dsi_sleep: mdss-dsi-sleep-state {
		pins = "gpio8";
		function = "gpio";
		drive-strength = <2>;
		bias-pull-down;
	};

	mdss_te_default: mdss-te-state {
		pins = "gpio10";
		function = "mdp_vsync";
		drive-strength = <2>;
		bias-pull-down;
	};

	panel_vddio_default: panel-vddio-default-state {
		pins = "gpio40";
		function = "gpio";
		drive-strength = <2>;
		bias-disable;
	};

	touch_default: touch-default-state {
		pins = "gpio89", "gpio125";
		function = "gpio";
		drive-strength = <16>;
		bias-pull-up;
	};

	touch_sleep: touch-sleep-state {
		pins = "gpio89", "gpio125";
		function = "gpio";
		drive-strength = <2>;
		bias-disable;
	};
};

&ufshc {
	status = "okay";

	vcc-supply = <&vreg_l20a_2p95>;
	vccq-supply = <&vreg_l25a_1p2>;
	vccq2-supply = <&vreg_s4a_1p8>;

	vcc-max-microamp = <600000>;
	vccq-max-microamp = <450000>;
	vccq2-max-microamp = <450000>;
};

&ufsphy {
	status = "okay";

	vdda-phy-supply = <&vreg_l28a_0p925>;
	vdda-pll-supply = <&vreg_l12a_1p8>;
};

/*
 * USB-C port, USB 2.0 through QUSB2 PHY 1 on the USB3 (dwc3) controller.
 * Dual role: the HD3SS3220 (blsp2_i2c1) switches between device (USB
 * networking / SSH) and host (OTG, VBUS from the SMBCHG boost).
 */
&usb3 {
	status = "okay";

	qcom,select-utmi-as-pipe-clk;
};

&usb3_dwc3 {
	/* role from the HD3SS3220; device mode until it says otherwise */
	usb-role-switch;
	role-switch-default-mode = "peripheral";

	/* usb3-phy is not used for now */
	phys = <&hsusb_phy1>;
	phy-names = "usb2-phy";

	dr_mode = "otg";
	maximum-speed = "high-speed";
	snps,is-utmi-l1-suspend;
	snps,usb2-gadget-lpm-disable;
	snps,hird-threshold = /bits/ 8 <0>;

	port {
		#address-cells = <1>;
		#size-cells = <0>;

		/* one per Type-C chip variant; only the fitted one probes */
		usb3_dwc3_role_in: endpoint@0 {
			reg = <0>;
			remote-endpoint = <&typec_hs_out>;
		};

		usb3_dwc3_role_pi: endpoint@1 {
			reg = <1>;
			remote-endpoint = <&pi5usb_hs_out>;
		};
	};
};

&venus {
	status = "okay";
	firmware-name = "qcom/msm8996/zte/axon7/venus.mbn";
};
